# STM32WL5x_CM0P register map
File version: 1.5
CPU: CM0 r0p1, little endian, MPU, no FPU, 4 interrupt priority bits
Registers are 32-bit, read-write, reset 0x0 unless marked. A register's access mark holds for its fields unless they carry their own. Offsets are from the block's base; [hi:lo] are bit positions.

## FLASH
Base 0x58004000
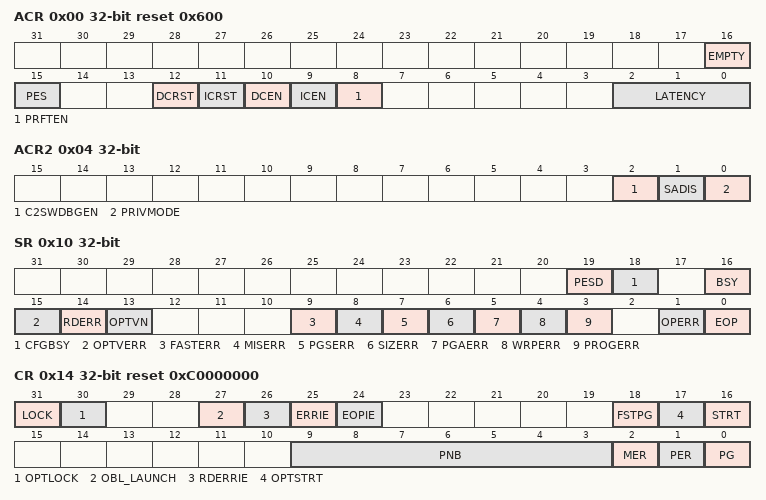
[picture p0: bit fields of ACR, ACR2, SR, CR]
0x00 ACR reset 0x600 — Access control register
  [16] EMPTY — Flash User area empty
  [15] PES — CPU1 programm erase suspend request
  [12] DCRST — Data cache reset
  [11] ICRST — Instruction cache reset
  [10] DCEN — Data cache enable
  [9] ICEN — Instruction cache enable
  [8] PRFTEN — Prefetch enable
  [2:0] LATENCY
0x04 ACR2 — Flash access control register 2
  [2] C2SWDBGEN — CPU2 Software debug enable
  [1] SADIS — Flash User sticky area access disable
  [0] PRIVMODE — CFI privileged mode enable
0x08 KEYR wo — Flash key register
  [31:0] KEY
0x0C OPTKEYR wo — Option byte key register
  [31:0] OPTKEYR — Option byte key
0x10 SR access per field — Status register
  [19] PESD ro — Programming / erase operation suspended
  [18] CFGBSY ro — Programming or erase configuration busy
  [16] BSY ro — Busy
  [15] OPTVERR rw — Option validity error
  [14] RDERR rw — PCROP read error
  [13] OPTVN ro — User Option OPTIVAL indication
  [9] FASTERR rw — Fast programming error
  [8] MISERR rw — Fast programming data miss error
  [7] PGSERR rw — Programming sequence error
  [6] SIZERR rw — Size error
  [5] PGAERR rw — Programming alignment error
  [4] WRPERR rw — Write protected error
  [3] PROGERR rw — Programming error
  [1] OPERR rw — Operation error
  [0] EOP rw — End of operation
0x14 CR reset 0xC0000000 — Flash control register
  [31] LOCK — FLASH_CR Lock
  [30] OPTLOCK — Options Lock
  [27] OBL_LAUNCH — Force the option byte loading
  [26] RDERRIE — PCROP read error interrupt enable
  [25] ERRIE — Error interrupt enable
  [24] EOPIE — End of operation interrupt enable
  [18] FSTPG — Fast programming
  [17] OPTSTRT — Options modification start
  [16] STRT — Start
  [9:3] PNB — Page number
  [2] MER — Mass erase
  [1] PER — Page erase
  [0] PG — Programming
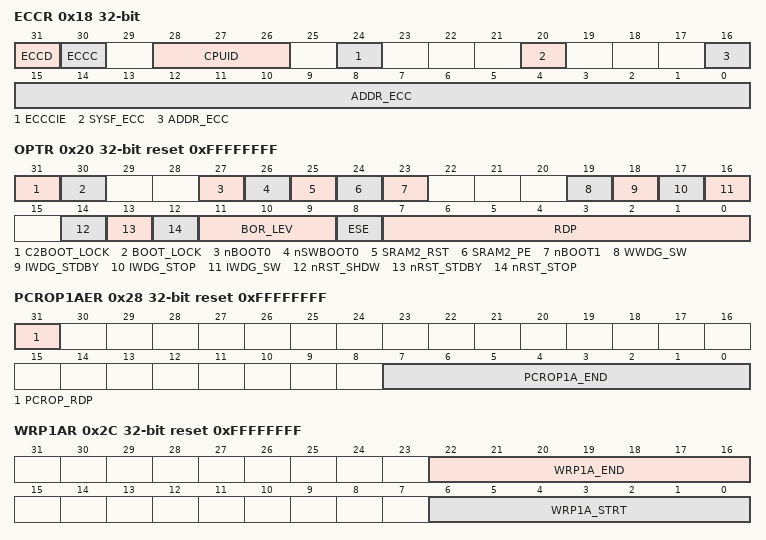
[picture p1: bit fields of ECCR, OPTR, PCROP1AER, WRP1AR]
0x18 ECCR access per field — Flash ECC register
  [31] ECCD rw — ECC detection
  [30] ECCC rw — ECC correction
  [28:26] CPUID ro — CPU identification
  [24] ECCCIE rw — ECC correction interrupt enable
  [20] SYSF_ECC ro — System Flash ECC fail
  [16:0] ADDR_ECC ro — ECC fail address
0x20 OPTR reset 0xFFFFFFFF — Flash option register
  [31] C2BOOT_LOCK — CPU2 CM0+ Unique Boot entry enable option bit
  [30] BOOT_LOCK — CPU1 CM4 Unique Boot entry enable option bit
  [27] nBOOT0 — nBOOT0 option bit
  [26] nSWBOOT0 — Software BOOT0 selection
  [25] SRAM2_RST — SRAM2 Erase when system reset
  [24] SRAM2_PE — SRAM2 parity check enable
  [23] nBOOT1 — Boot configuration
  [19] WWDG_SW — Window watchdog selection
  [18] IWDG_STDBY — Independent watchdog counter freeze in Standby mode
  [17] IWDG_STOP — Independent watchdog counter freeze in Stop mode
  [16] IWDG_SW — Independent watchdog selection
  [14] nRST_SHDW
  [13] nRST_STDBY
  [12] nRST_STOP
  [11:9] BOR_LEV — BOR reset Level
  [8] ESE — System security enabled flag
  [7:0] RDP — Read protection level
0x24 PCROP1ASR ro reset 0xFFFFFFFF — Flash PCROP zone A Start address register
  [7:0] PCROP1A_STRT — PCROP1A area start offset
0x28 PCROP1AER access per field reset 0xFFFFFFFF — Flash PCROP zone A End address register
  [31] PCROP_RDP rw — PCROP area preserved when RDP level decreased
  [7:0] PCROP1A_END ro — PCROP area end offset
0x2C WRP1AR ro reset 0xFFFFFFFF — Flash WRP area A address register
  [22:16] WRP1A_END — Bank 1 WRP first area A end offset
  [6:0] WRP1A_STRT — Bank 1 WRP first area start offset
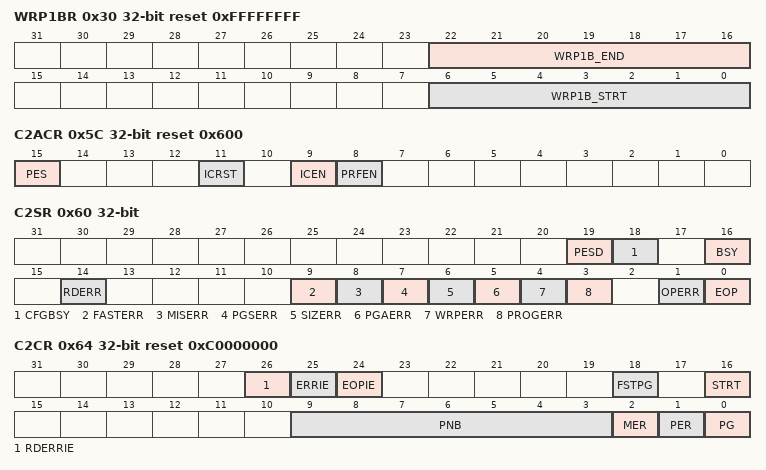
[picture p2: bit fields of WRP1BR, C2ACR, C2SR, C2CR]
0x30 WRP1BR ro reset 0xFFFFFFFF — Flash WRP area B address register
  [22:16] WRP1B_END — Bank 1 WRP second area B start offset
  [6:0] WRP1B_STRT — Bank 1 WRP second area B end offset
0x34 PCROP1BSR ro reset 0xFFFFFFFF — Flash PCROP zone B Start address register
  [7:0] PCROP1B_STRT — Bank 1 WRP second area B end offset
0x38 PCROP1BER reset 0xFFFFFFFF — Flash PCROP zone B End address register
  [7:0] PCROP1B_END — PCROP1B area end offset
0x3C IPCCBR reset 0xFFFFFFFF — Flash IPCC data buffer address register
  [13:0] IPCCDBA
0x5C C2ACR reset 0x600 — Flash CPU2 access control register
  [15] PES — CPU2 program / erase suspend request
  [11] ICRST — CPU2 Instruction cache reset
  [9] ICEN — CPU2 Instruction cache enable
  [8] PRFEN — CPU2 Prefetch enable
0x60 C2SR access per field — Flash CPU2 status register
  [19] PESD ro
  [18] CFGBSY ro
  [16] BSY ro
  [14] RDERR rw — PCROP read error
  [9] FASTERR rw — Fast programming error
  [8] MISERR rw — Fast programming data miss error
  [7] PGSERR rw — Programming sequence error
  [6] SIZERR rw — Size error
  [5] PGAERR rw
  [4] WRPERR rw
  [3] PROGERR rw — Programming error
  [1] OPERR rw — Operation error
  [0] EOP rw — End of operation
0x64 C2CR reset 0xC0000000 — Flash CPU2 control register
  [26] RDERRIE
  [25] ERRIE — Error interrupt enable
  [24] EOPIE — End of operation interrupt enable
  [18] FSTPG — Fast programming
  [16] STRT — Start
  [9:3] PNB — Page number selection
  [2] MER — Mass erase
  [1] PER — Page erase
  [0] PG — Programming
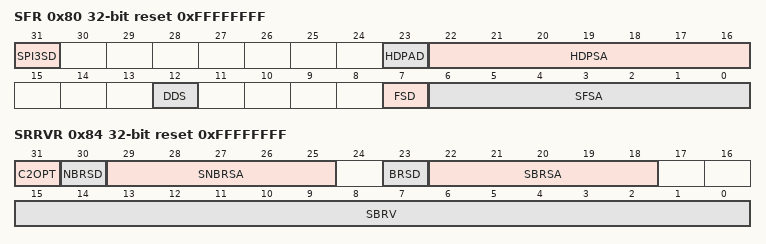
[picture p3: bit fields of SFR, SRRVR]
0x80 SFR reset 0xFFFFFFFF — Flash secure Flash start address register
  [31] SPI3SD — SPI3 security disable
  [23] HDPAD — User Flash hide protection area disabled
  [22:16] HDPSA — User Flash hide protection area start address
  [12] DDS
  [7] FSD — Flash security disabled
  [6:0] SFSA — Secure Flash start address
0x84 SRRVR reset 0xFFFFFFFF — Flash secure SRAM start address and CPU2 reset vector register
  [31] C2OPT
  [30] NBRSD
  [29:25] SNBRSA — Secure non-backup SRAM1 start address
  [23] BRSD — backup SRAM2 security disable
  [22:18] SBRSA — Secure backup SRAM2 start address
  [15:0] SBRV — CPU2 boot reset vector
